# VPE_TOP_LEVEL register map
Vendor: Texas Instruments
Peripheral module from a debugger description file (folder DRA75x_DRA74x).
Registers are 32-bit, access per field, reset 0x0 unless marked. A register's access mark holds for its fields unless they carry their own. Offsets are as the file gives them; lines under a group give offsets from that group; [hi:lo] are bit positions; {n}, {i} and the like mark numbered series; 'fields as' and 'values as' point back to an identical list; <NAME> marks a mode.

## VPE_TOP_LEVEL
0x00 VPE_CLKC_PID ro
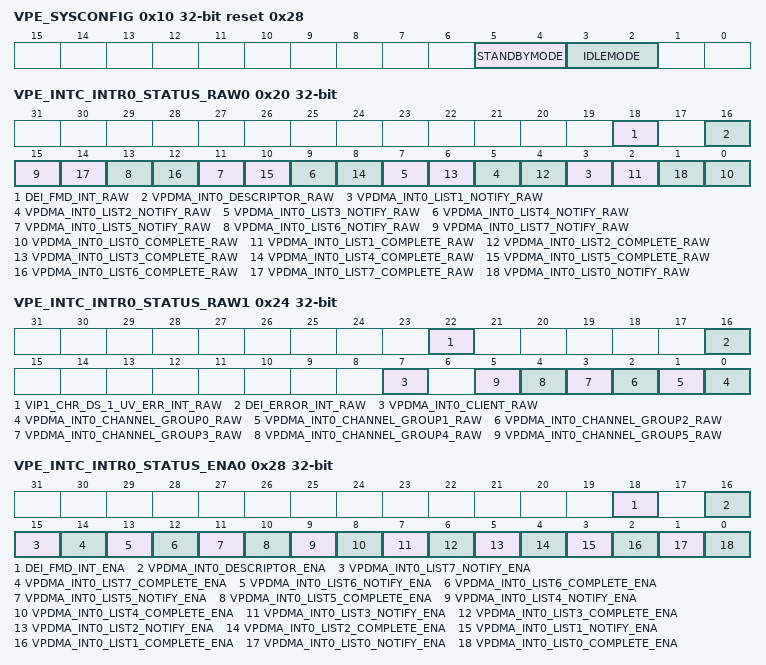
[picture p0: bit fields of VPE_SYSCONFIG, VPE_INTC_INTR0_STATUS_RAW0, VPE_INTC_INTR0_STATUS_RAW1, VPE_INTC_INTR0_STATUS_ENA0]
0x10 VPE_SYSCONFIG reset 0x28
  [5:4] STANDBYMODE rw — Configuration of the local initiator state management mode. By definition, initiator may generate read/write transaction as long as it is out of STANDBY state 0x0: Force-standby mode: local initiator is unconditionally placed in standby state. Backup mode, for debug only 0x1: No-standby mode: local initiator is unconditionally placed out of standby state. Backup mode, for debug only 0x2: Same behavior as bit-field value of 0x1. 0x3: Reserved
  [3:2] IDLEMODE rw — Configuration of the local target state management mode. By definition, target can handle read/write transaction as long as it is out of IDLE state 0x0: Force-idle mode: local target's idle state follows (acknowledges) the system's idle requests unconditionally, i.e. regardless of the IP module's internal requirements. Backup mode, for debug only 0x1: No-idle mode: local target never enters idle state. Backup mode, for debug only 0x2: Smart-idle mode: local target's idle state eventually follows (acknowledges) the system's idle requests, depending on the IP module's internal requirements. IP module shall not generate (IRQ- or DMA-request-related) wakeup events 0x3: Smart-idle wakeup-capable mode: local target's idle state eventually follows (acknowledges) the system's idle requests, depending on the IP module's internal requirements. IP module may generate (IRQ- or DMA-request-related) wakeup events when in idle state. Mode is only relevant if the appropriate IP module 'swakeup' output(s) is (are) implemented
0x20 VPE_INTC_INTR0_STATUS_RAW0
  [18] DEI_FMD_INT_RAW rw — DEI Film Mode Interrupt Status Read indicates raw status 0 = inactive 1 = active Writing 1 will set status Writing 0 has no effect
  [16] VPDMA_INT0_DESCRIPTOR_RAW rw — VPDMA INT0 Descriptor Status Read indicates raw status 0 = inactive 1 = active Writing 1 will set status Writing 0 has no effect
  [2n+1] VPDMA_INT0_LIST{n}_NOTIFY_RAW rw (n=1..7) — VPDMA INT0 List{n} Complete Status Read indicates raw status 0 = inactive 1 = active Writing 1 will set status Writing 0 has no effect
  [2n] VPDMA_INT0_LIST{n}_COMPLETE_RAW rw (n=0..7) — VPDMA INT0 List{n} Complete Status Read indicates raw status 0 = inactive 1 = active Writing 1 will set status Writing 0 has no effect
  [1] VPDMA_INT0_LIST0_NOTIFY_RAW rw — VPDMA INT0 List0 Notify Status Read indicates raw status 0 = inactive 1 = active Writing 1 will set status Writing 0 has no effect
0x24 VPE_INTC_INTR0_STATUS_RAW1
  [22] VIP1_CHR_DS_1_UV_ERR_INT_RAW rw — VIP1 Chroma Downsampler 1 UV Error Interrupt Status Read indicates raw status 0 = inactive 1 = active Writing 1 will set status Writing 0 has no effect
  [16] DEI_ERROR_INT_RAW rw — DEI Error Interrupt Status Read indicates raw status 0 = inactive 1 = active Writing 1 will set status Writing 0 has no effect
  [7] VPDMA_INT0_CLIENT_RAW rw — VPDMA INT0 Client Status Read indicates raw status 0 = inactive 1 = active Writing 1 will set status Writing 0 has no effect
  [n] VPDMA_INT0_CHANNEL_GROUP{n}_RAW rw (n=0..5) — VPDMA INT0 Channel Group{n} Status Read indicates raw status 0 = inactive 1 = active Writing 1 will set status Writing 0 has no effect
0x28 VPE_INTC_INTR0_STATUS_ENA0
  [18] DEI_FMD_INT_ENA rw — DEI Film Mode Enabled Status Read indicates interrupt enable 0 = disabled 1 = enabled Writing 1 will set interrupt enabled Writing 0 has no effect
  [16] VPDMA_INT0_DESCRIPTOR_ENA rw — VPDMA INT0 Descriptor Enabled Status Read indicates interrupt enable 0 = disabled 1 = enabled Writing 1 will set interrupt enabled Writing 0 has no effect
  [15] VPDMA_INT0_LIST7_NOTIFY_ENA rw — VPDMA INT0 List7 Notify Enabled Status Read indicates interrupt enable 0 = disabled 1 = enabled Writing 1 will set interrupt enabled Writing 0 has no effect
  [14] VPDMA_INT0_LIST7_COMPLETE_ENA rw — VPDMA INT0 List7 Complete Enabled Status Read indicates interrupt enable 0 = disabled 1 = enabled Writing 1 will set interrupt enabled Writing 0 has no effect
  [13] VPDMA_INT0_LIST6_NOTIFY_ENA rw — VPDMA INT0 List6 Notify Enabled Status Read indicates interrupt enable 0 = disabled 1 = enabled Writing 1 will set interrupt enabled Writing 0 has no effect
  [12] VPDMA_INT0_LIST6_COMPLETE_ENA rw — VPDMA INT0 List6 Complete Enabled Status Read indicates interrupt enable 0 = disabled 1 = enabled Writing 1 will set interrupt enabled Writing 0 has no effect
  [11] VPDMA_INT0_LIST5_NOTIFY_ENA rw — VPDMA INT0 List5 Notify Enabled Status Read indicates interrupt enable 0 = disabled 1 = enabled Writing 1 will set interrupt enabled Writing 0 has no effect
  [10] VPDMA_INT0_LIST5_COMPLETE_ENA rw — VPDMA INT0 List5 Complete Enabled Statust Read indicates interrupt enable 0 = disabled 1 = enabled Writing 1 will set interrupt enabled Writing 0 has no effect
  [9] VPDMA_INT0_LIST4_NOTIFY_ENA rw — VPDMA INT0 List4 Notify Enabled Statust Read indicates interrupt enable 0 = disabled 1 = enabled Writing 1 will set interrupt enabled Writing 0 has no effect
  [8] VPDMA_INT0_LIST4_COMPLETE_ENA rw — VPDMA INT0 List4 Complete Enabled Status Read indicates interrupt enable 0 = disabled 1 = enabled Writing 1 will set interrupt enabled Writing 0 has no effect
  [7] VPDMA_INT0_LIST3_NOTIFY_ENA rw — VPDMA INT0 List3 Notify Enabled Status Read indicates interrupt enable 0 = disabled 1 = enabled Writing 1 will set interrupt enabled Writing 0 has no effect
  [6] VPDMA_INT0_LIST3_COMPLETE_ENA rw — VPDMA INT0 List3 Complete Enabled Status Read indicates interrupt enable 0 = disabled 1 = enabled Writing 1 will set interrupt enabled Writing 0 has no effect
  [5] VPDMA_INT0_LIST2_NOTIFY_ENA rw — VPDMA INT0 List2 Notify Enabled Statust Read indicates interrupt enable 0 = disabled 1 = enabled Writing 1 will set interrupt enabled Writing 0 has no effect
  [4] VPDMA_INT0_LIST2_COMPLETE_ENA rw — VPDMA INT0 List2 Complete Enabled Statust Read indicates interrupt enable 0 = disabled 1 = enabled Writing 1 will set interrupt enabled Writing 0 has no effect
  [3] VPDMA_INT0_LIST1_NOTIFY_ENA rw — VPDMA INT0 List1 Notify Enabled Status Read indicates interrupt enable 0 = disabled 1 = enabled Writing 1 will set interrupt enabled Writing 0 has no effect
  [2] VPDMA_INT0_LIST1_COMPLETE_ENA rw — VPDMA INT0 List1 Complete Enabled Status Read indicates interrupt enable 0 = disabled 1 = enabled Writing 1 will set interrupt enabled Writing 0 has no effect
  [1] VPDMA_INT0_LIST0_NOTIFY_ENA rw — VPDMA INT0 List0 Notify Enabled Status Read indicates interrupt enable 0 = disabled 1 = enabled Writing 1 will set interrupt enabled Writing 0 has no effect
  [0] VPDMA_INT0_LIST0_COMPLETE_ENA rw — VPDMA INT0 List0 Complete Enabled Status Read indicates interrupt enable 0 = disabled 1 = enabled Writing 1 will set interrupt enabled Writing 0 has no effect
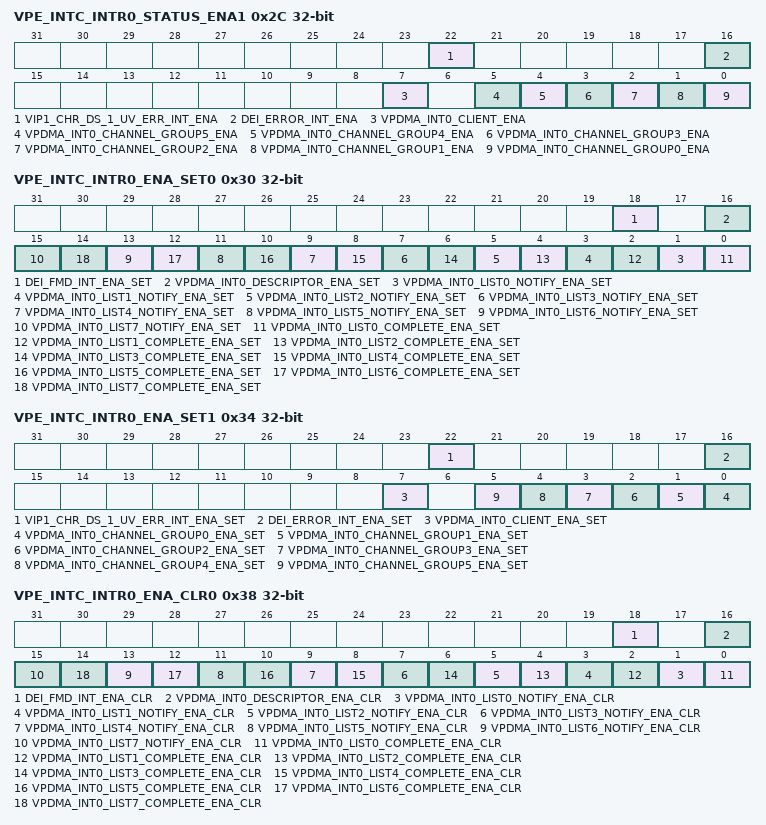
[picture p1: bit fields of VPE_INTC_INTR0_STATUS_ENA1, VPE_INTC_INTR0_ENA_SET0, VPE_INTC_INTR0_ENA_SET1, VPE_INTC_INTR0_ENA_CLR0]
0x2C VPE_INTC_INTR0_STATUS_ENA1
  [22] VIP1_CHR_DS_1_UV_ERR_INT_ENA rw — VIP1 Chroma Downsampler 1 UV Error Enabled Interrupt Status Read indicates enabled status 0 = inactive 1 = active Writing 1 will clear interrupt Writing 0 has no effect
  [16] DEI_ERROR_INT_ENA rw — DEI Error Enabled Interrupt Status Read indicates enabled status 0 = inactive 1 = active Writing 1 will clear interrupt Writing 0 has no effect
  [7] VPDMA_INT0_CLIENT_ENA rw — VPDMA INT0 Client Enabled Status Read indicates raw status 0 = inactive 1 = active Writing 1 will set status Writing 0 has no effect
  [5] VPDMA_INT0_CHANNEL_GROUP5_ENA rw — VPDMA INT0 Channel Group5 Enabled Status Read indicates raw status 0 = inactive 1 = active Writing 1 will set status Writing 0 has no effect
  [4] VPDMA_INT0_CHANNEL_GROUP4_ENA rw — VPDMA INT0 Channel Group4 Enabled Status Read indicates raw status 0 = inactive 1 = active Writing 1 will set status Writing 0 has no effect
  [3] VPDMA_INT0_CHANNEL_GROUP3_ENA rw — VPDMA INT0 Channel Group3 Enabled Status Read indicates raw status 0 = inactive 1 = active Writing 1 will set status Writing 0 has no effect
  [2] VPDMA_INT0_CHANNEL_GROUP2_ENA rw — VPDMA INT0 Channel Group3 Enabled Status Read indicates raw status 0 = inactive 1 = active Writing 1 will set status Writing 0 has no effect
  [1] VPDMA_INT0_CHANNEL_GROUP1_ENA rw — VPDMA INT0 Channel Group1 Enabled Status Read indicates raw status 0 = inactive 1 = active Writing 1 will set status Writing 0 has no effect
  [0] VPDMA_INT0_CHANNEL_GROUP0_ENA rw — VPDMA INT0 Channel Group0 Enabled Status Read indicates raw status 0 = inactive 1 = active Writing 1 will set status Writing 0 has no effect
0x30 VPE_INTC_INTR0_ENA_SET0
  [18] DEI_FMD_INT_ENA_SET rw — DEI Film Mode Enable/Set Read indicates interrupt enable 0 = disabled 1 = enabled Writing 1 will set interrupt enabled Writing 0 has no effect
  [16] VPDMA_INT0_DESCRIPTOR_ENA_SET rw — VPDMA INT0 Descriptor Enable/Set Read indicates interrupt enable 0 = disabled 1 = enabled Writing 1 will set interrupt enabled Writing 0 has no effect
  [2n+1] VPDMA_INT0_LIST{n}_NOTIFY_ENA_SET rw (n=0..7) — VPDMA INT0 List{n} Notify Enable/Set Read indicates interrupt enable 0 = disabled 1 = enabled Writing 1 will set interrupt enabled Writing 0 has no effect
  [2n] VPDMA_INT0_LIST{n}_COMPLETE_ENA_SET rw (n=0..7) — VPDMA INT0 List{n} Complete Enable/Set Read indicates interrupt enable 0 = disabled 1 = enabled Writing 1 will set interrupt enabled Writing 0 has no effect
0x34 VPE_INTC_INTR0_ENA_SET1
  [22] VIP1_CHR_DS_1_UV_ERR_INT_ENA_SET rw — VIP1 Chroma Downsampler 1 UV Error Enable/Set Read indicates interrupt enable 0 = disabled 1 = enabled Writing 1 will set interrupt enabled Writing 0 has no effect
  [16] DEI_ERROR_INT_ENA_SET rw — DEI Error Enable/Set Read indicates interrupt enable 0 = disabled 1 = enabled Writing 1 will set interrupt enabled Writing 0 has no effect
  [7] VPDMA_INT0_CLIENT_ENA_SET rw — VPDMA INT0 Client Enable/Set Read indicates interrupt enable 0 = disabled 1 = enabled Writing 1 will set interrupt enabled Writing 0 has no effect
  [n] VPDMA_INT0_CHANNEL_GROUP{n}_ENA_SET rw (n=0..5) — VPDMA INT0 Channel Group{n} Enable/Set Read indicates interrupt enable 0 = disabled 1 = enabled Writing 1 will set interrupt enabled Writing 0 has no effect
0x38 VPE_INTC_INTR0_ENA_CLR0
  [18] DEI_FMD_INT_ENA_CLR rw — DEI Film Mode Enable/Clear Read indicates interrupt enable 0 = disabled 1 = enabled Writing 1 will clear interrupt enabled Writing 0 has no effect
  [16] VPDMA_INT0_DESCRIPTOR_ENA_CLR rw — VPDMA INT0 Descriptor Enable/Clear Read indicates interrupt enable 0 = disabled 1 = enabled Writing 1 will clear interrupt enabled Writing 0 has no effect
  [2n+1] VPDMA_INT0_LIST{n}_NOTIFY_ENA_CLR rw (n=0..7) — VPDMA INT0 List{n} Notify Enable/Clear Read indicates interrupt enable 0 = disabled 1 = enabled Writing 1 will clear interrupt enabled Writing 0 has no effect
  [2n] VPDMA_INT0_LIST{n}_COMPLETE_ENA_CLR rw (n=0..7) — VPDMA INT0 List{n} Complete Enable/Clear Read indicates interrupt enable 0 = disabled 1 = enabled Writing 1 will clear interrupt enabled Writing 0 has no effect
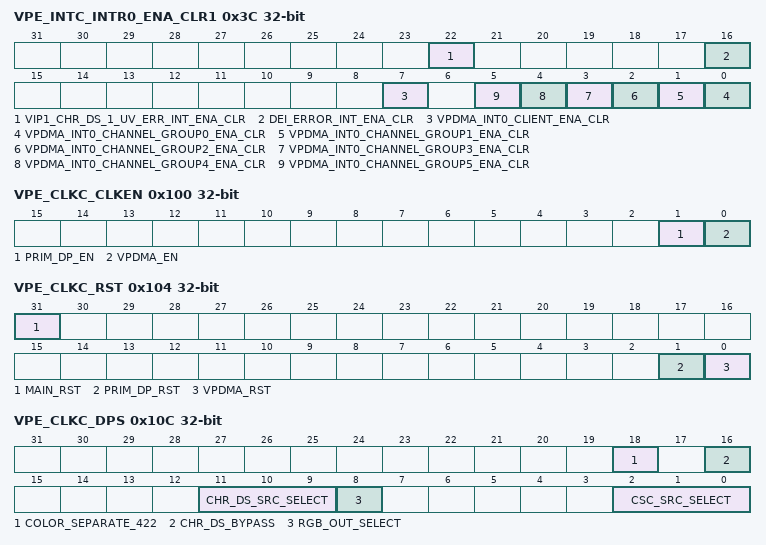
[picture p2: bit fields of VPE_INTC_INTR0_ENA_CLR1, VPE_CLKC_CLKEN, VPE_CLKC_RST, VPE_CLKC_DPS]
0x3C VPE_INTC_INTR0_ENA_CLR1
  [22] VIP1_CHR_DS_1_UV_ERR_INT_ENA_CLR rw — VIP1 Chroma Downsampler 1 UV Error Enable/Clear Read indicates interrupt enable 0 = disabled 1 = enabled Writing 1 will clear interrupt enabled Writing 0 has no effect
  [16] DEI_ERROR_INT_ENA_CLR rw — DEI Error Enable/Clear Read indicates interrupt enable 0 = disabled 1 = enabled Writing 1 will clear interrupt enabled Writing 0 has no effect
  [7] VPDMA_INT0_CLIENT_ENA_CLR rw — VPDMA INT0 Client Enable/Clear Read indicates interrupt enable 0 = disabled 1 = enabled Writing 1 will clear interrupt enabled Writing 0 has no effect
  [n] VPDMA_INT0_CHANNEL_GROUP{n}_ENA_CLR rw (n=0..5) — VPDMA INT0 Channel Group{n} Enable/Clear Read indicates interrupt enable 0 = disabled 1 = enabled Writing 1 will clear interrupt enabled Writing 0 has no effect
0xA0 VPE_INTC_EOI rw — INTC EOI Register. This register contains the EOI vector register contents as defined by HL0.8
  [31:0] EOI_VECTOR — Number associated with the ipgenericirq for intr output. There are 4 interrupt outputs:Any other write value is ignored. .
    {v}=Write_to_intr{v}_IP_Generic (v=0..3)
0x100 VPE_CLKC_CLKEN
  [1] PRIM_DP_EN rw — Primary Video Data Path Clock Enable
    0=Clock_Disabled; 1=Clock_Enabled
  [0] VPDMA_EN rw — VPDMA Clock Enable
    0=Clock_Disabled; 1=Clock_Enabled
0x104 VPE_CLKC_RST
  [31] MAIN_RST rw — Reset for entire data path in VPE0
  [1] PRIM_DP_RST rw — Primary Video Data Path Reset
  [0] VPDMA_RST rw — VPDMA Reset
0x10C VPE_CLKC_DPS
  [18] COLOR_SEPARATE_422 rw — 422 Color Separate SelectThis bit controls whether 422 output will be color separate or interleaved. This bit only applies IF chr_ds_bypass is 1 (means 422 output, not 420) and rgb_out_select is 0 (means 422 output, not RGB or 444). 420 is always coplanar, so this only applies if the output type is 422. . .
    0=422 output will be 16 bit interleaved (YCbCr); 1=(Y,_1 (422 output will be 8 bit coplanar (Y, CbCr))
  [16] CHR_DS_BYPASS rw — Chroma Downsampler Bypass
    0=Chroma_Downsampler_selected; 1=VPE0_1 (Chroma Downsampler Bypassed Chroma Downsampler Bypassed means the output format from VPE0 will be 422 data. Selected means the output format will be 420. This bit is only applicable if rgb_out_select is 0. It is a don't care if rgb_out_select is 1.)
  [11:9] CHR_DS_SRC_SELECT rw — Chroma Downsampler Source Select
  [8] RGB_OUT_SELECT rw — RGB Output Select
    0=Output_Type_is_420/422; 1=Output_Type_is_RGB/444
  [2:0] CSC_SRC_SELECT rw — CSC Source Select:
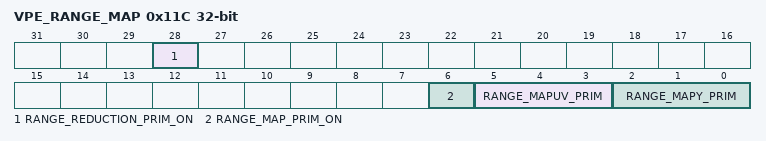
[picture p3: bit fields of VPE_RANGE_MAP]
0x11C VPE_RANGE_MAP
  [28] RANGE_REDUCTION_PRIM_ON rw — Range Reduction ON for Primary input
  [6] RANGE_MAP_PRIM_ON rw — Range Mapping ON for Primary input
  [5:3] RANGE_MAPUV_PRIM rw — Range Map UV for Primary input
  [2:0] RANGE_MAPY_PRIM rw — Range Map Y for Primary input
